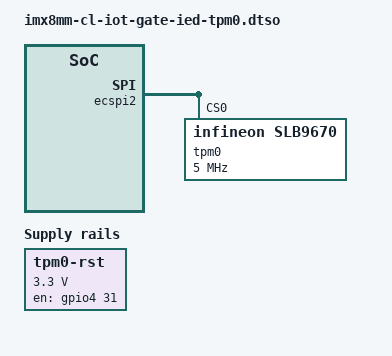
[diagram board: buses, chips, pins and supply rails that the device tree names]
// SPDX-License-Identifier: (GPL-2.0+ OR MIT)
/*
 * Copyright 2021 Linaro
 */

/dts-v1/;
/plugin/;

#include <dt-bindings/gpio/gpio.h>

#include "imx8mm-pinfunc.h"

&{/} {
	regulatot-tpm0-rst {
		compatible = "regulator-fixed";
		regulator-name = "tpm0-rst";
		regulator-min-microvolt = <3300000>;
		regulator-max-microvolt = <3300000>;
		gpio = <&gpio4 31 GPIO_ACTIVE_HIGH>;
		regulator-always-on;
		enable-active-high;
	};
};

&ecspi2 {
	#address-cells = <1>;
	#size-cells = <0>;

	tpm0: tpm@0 {
		compatible = "infineon,slb9670", "tcg,tpm_tis-spi";
		reg = <0>;
		pinctrl-names = "default";
		pinctrl-0 = <&pinctrl_tpm0>;
		spi-max-frequency = <5000000>;
		status = "okay";
	};
};

&iomuxc {
	pinctrl_tpm0: tpm0grp {
		fsl,pins = <
			MX8MM_IOMUXC_SAI3_TXFS_GPIO4_IO31       0x0
		>;
	};
};
